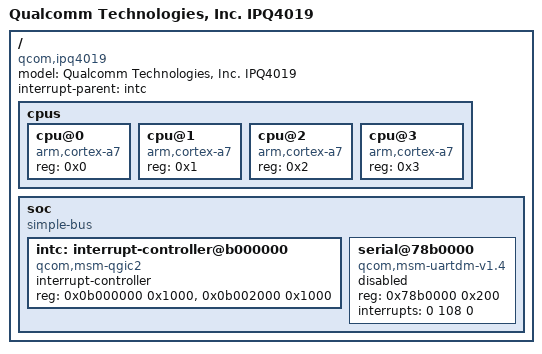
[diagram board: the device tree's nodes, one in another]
/*
 * Copyright (c) 2015, The Linux Foundation. All rights reserved.
 *
 * This program is free software; you can redistribute it and/or modify
 * it under the terms of the GNU General Public License version 2 and
 * only version 2 as published by the Free Software Foundation.
 *
 * This program is distributed in the hope that it will be useful,
 * but WITHOUT ANY WARRANTY; without even the implied warranty of
 * MERCHANTABILITY or FITNESS FOR A PARTICULAR PURPOSE.  See the
 * GNU General Public License for more details.
 */

/dts-v1/;

#include "skeleton.dtsi"

/ {
	model = "Qualcomm Technologies, Inc. IPQ4019";
	compatible = "qcom,ipq4019";
	interrupt-parent = <&intc>;

	cpus {
		#address-cells = <1>;
		#size-cells = <0>;
		cpu@0 {
			device_type = "cpu";
			compatible = "arm,cortex-a7";
			reg = <0x0>;
		};

		cpu@1 {
			device_type = "cpu";
			compatible = "arm,cortex-a7";
			reg = <0x1>;
		};

		cpu@2 {
			device_type = "cpu";
			compatible = "arm,cortex-a7";
			reg = <0x2>;
		};

		cpu@3 {
			device_type = "cpu";
			compatible = "arm,cortex-a7";
			reg = <0x3>;
		};
	};

	soc {
		#address-cells = <1>;
		#size-cells = <1>;
		ranges;
		compatible = "simple-bus";

		intc: interrupt-controller@b000000 {
			compatible = "qcom,msm-qgic2";
			interrupt-controller;
			#interrupt-cells = <3>;
			reg = <0x0b000000 0x1000>,
			<0x0b002000 0x1000>;
		};

		serial@78b0000 {
			compatible = "qcom,msm-uartdm-v1.4", "qcom,msm-uartdm";
			reg = <0x78b0000 0x200>;
			interrupts = <0 108 0>;
			status = "disabled";
		};
	};
};
